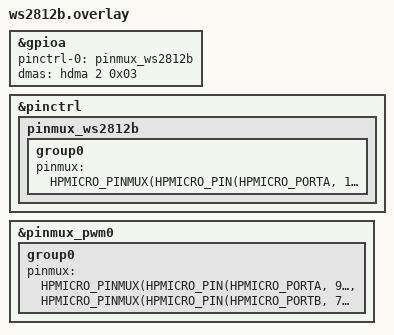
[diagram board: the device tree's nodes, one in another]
/* PA10 stays on the same PCB wire: GPTMR0 CH2 generates hardware edges.
 * Synchronized CH3 updates the next bit via DMA (DMAMUX source 0x03).
 * PWM0 and its reload register are exclusively owned by the IMU heater.
 */
&gpioa {
    pinctrl-0 = <&pinmux_ws2812b>;
    pinctrl-names = "default";
    dmas = <&hdma 2 0x03>;
    dma-names = "ws2812b";
};

&pinctrl {
    pinmux_ws2812b: pinmux_ws2812b {
        group0 {
            pinmux = <HPMICRO_PINMUX(HPMICRO_PIN(HPMICRO_PORTA, 10), IOC_TYPE_IOC, 0, 0)>;
        };
    };
};

&pinmux_pwm0 {
    group0 {
        pinmux = <HPMICRO_PINMUX(HPMICRO_PIN(HPMICRO_PORTA, 9), IOC_TYPE_IOC, 0, 16)>,
                 <HPMICRO_PINMUX(HPMICRO_PIN(HPMICRO_PORTB, 7), IOC_TYPE_IOC, 0, 16)>;
    };
};
